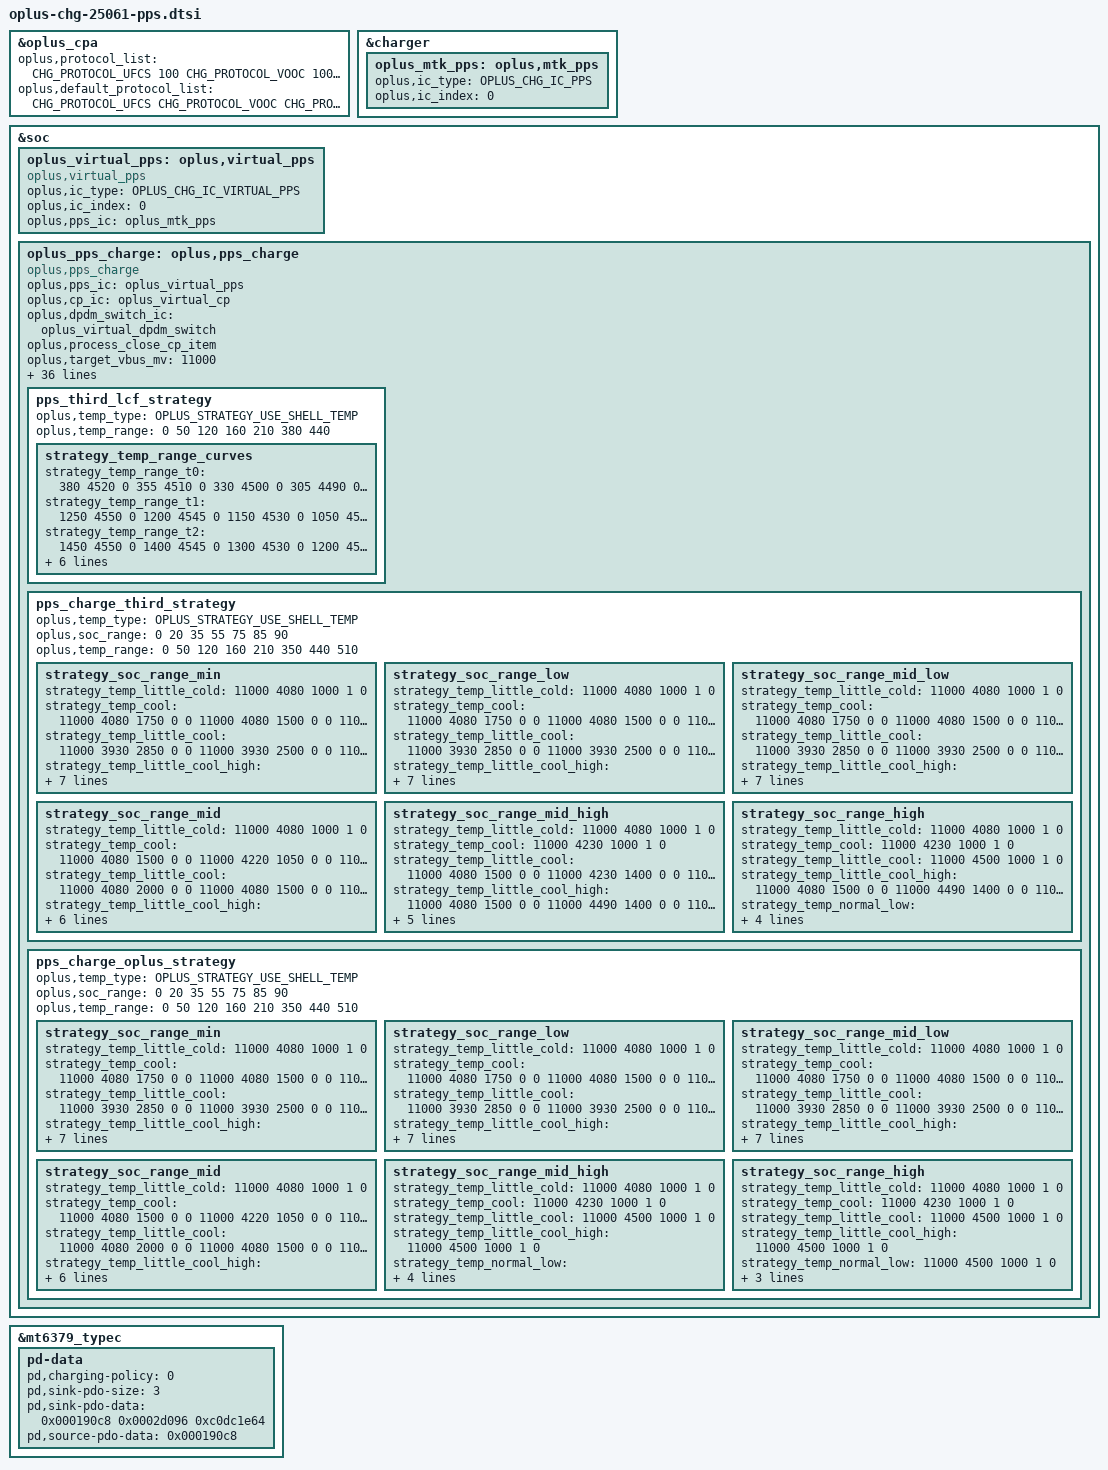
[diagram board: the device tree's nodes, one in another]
//ifdef OPLUS_FEATURE_CHG_BASIC
&oplus_cpa {
	oplus,protocol_list = <CHG_PROTOCOL_UFCS 100
			       CHG_PROTOCOL_VOOC 100
			       CHG_PROTOCOL_PPS 55
			       CHG_PROTOCOL_PD 18
			       CHG_PROTOCOL_QC 18>;
	oplus,default_protocol_list = <CHG_PROTOCOL_UFCS
				       CHG_PROTOCOL_VOOC
				       CHG_PROTOCOL_PPS
				       CHG_PROTOCOL_PD>;
};

&charger {
	oplus_mtk_pps: oplus,mtk_pps {
		oplus,ic_type = <OPLUS_CHG_IC_PPS>;
		oplus,ic_index = <0>;
	};
};
&soc {
	oplus_virtual_pps: oplus,virtual_pps {
		compatible = "oplus,virtual_pps";

		oplus,ic_type = <OPLUS_CHG_IC_VIRTUAL_PPS>;
		oplus,ic_index = <0>;
		oplus,pps_ic = <&oplus_mtk_pps>;
	};
	oplus_pps_charge: oplus,pps_charge {
		compatible = "oplus,pps_charge";
		oplus,pps_ic = <&oplus_virtual_pps>;
		oplus,cp_ic = <&oplus_virtual_cp>;
		oplus,dpdm_switch_ic = <&oplus_virtual_dpdm_switch>;
		oplus,process_close_cp_item;

		oplus,target_vbus_mv = <11000>;
		oplus,curr_max_ma = <5000>;
		oplus,curr_max_ma_percent = <2500 /* 75% ibus */
 					     1000 /* 85% ibus */>;

		oplus,pps_warm_allow_vol = <4000>;
		oplus,pps_warm_allow_soc = <55>;
		oplus,pps_strategy_normal_current = <5000>;
		oplus,pps_over_high_or_low_current = <3000>;
		oplus,pps_timeout_third = <19954>;
		oplus,pps_timeout_oplus = <19954>;
		oplus,pps_ibat_over_third = <11400>;
		oplus,pps_ibat_over_oplus = <11400>;
		oplus,pps_full_cool_sw_vbat = <4230>;
		oplus,pps_full_normal_sw_vbat = <4500>;
		oplus,pps_full_normal_hw_vbat = <4540>;
		oplus,pps_full_warm_vbat = <4130>;
		oplus,pps_full_cool_sw_vbat_third = <4230>;
		oplus,pps_full_normal_sw_vbat_third= <4500>;
		oplus,pps_full_normal_hw_vbat_third = <4540>;
		oplus,pps_current_change_timeout = <100>;
		oplus,pps_strategy_batt_high_temp = <410 430 435 400 425 430>;
		oplus,pps_strategy_high_current = <3000 3000 2000 3000 3000 3000>;
		oplus,pps_little_cool_high_temp = <210>;
		oplus,pps_low_temp = <50>;
		oplus,curve_strategy_name = "pps_ufcs_curve_v2";
		oplus,pps_charge_strategy_soc = <0 20 35 55 75 85 90>;
		oplus,pps_charge_strategy_temp = <50 50 120 160 350 440 510>;
		oplus,pps_full_recheck_temp = <210>;

		oplus,pps_vfa_strategy = <&ratio2t1_vfa_strategy>;

		oplus,plc_strategy-data = <&pps_simple_strategy>;
		oplus,plc_strategy-names = "default";

		oplus,temperature_strategy_name = "cgcl";
		oplus,temperature_strategy_data = < OPLUS_STRATEGY_USE_SHELL_TEMP
							0   400 5000 1 0
							395 420 4000 2 0
							410 430 3000 3 1
							425 440 2500 4 2
							435 450 2000 4 3>;

		pps_third_lcf_strategy {
			oplus,temp_type = <OPLUS_STRATEGY_USE_SHELL_TEMP>;
			oplus,temp_range = <0 50 120 160 210 380 440>;

			strategy_temp_range_curves {
				strategy_temp_range_t0 =	<380 4520 0
								 355 4510 0
								 330 4500 0
								 305 4490 0
								 280 4480 1>;
				strategy_temp_range_t1 =	<1250 4550 0
								 1200 4545 0
								 1150 4530 0
								 1050 4520 0
								 950 4510 1>;
				strategy_temp_range_t2 =	<1450 4550 0
								 1400 4545 0
								 1300 4530 0
								 1200 4520 0
								 1050 4510 1>;
				strategy_temp_range_t3 =	<1550 4550 0
								 1500 4545 0
								 1400 4530 0
								 1300 4520 0
								 1150 4510 1>;
				strategy_temp_range_t4 =	<2100 4543 0
								 1900 4539 0
								 1600 4535 0
								 1300 4525 0
								 1000 4515 1>;
				strategy_temp_range_t5 =	<3550 4543 0
								 3350 4538 0
								 2600 4515 0
								 1850 4500 0
								 1000 4480 1>;
			};
		};

		pps_charge_third_strategy {
			oplus,temp_type = <OPLUS_STRATEGY_USE_SHELL_TEMP>;
			oplus,soc_range = <0 20 35 55 75 85 90>;
			oplus,temp_range = <0 50 120 160 210 350 440 510>;

			strategy_soc_range_min {
				strategy_temp_little_cold =	<11000 4080 1000 1 0>;
				strategy_temp_cool =		<11000 4080 1750 0 0
								11000 4080 1500 0 0
								11000 4220 1050 0 0
								11000 4230 1000 1 0>;
				strategy_temp_little_cool =	<11000 3930 2850 0 0
								11000 3930 2500 0 0
								11000 4080 2100 0 0
								11000 4080 2000 0 0
								11000 4080 1500 0 0
								11000 4230 1400 0 0
								11000 4490 1050 0 0
								11000 4500 1000 1 0>;
				strategy_temp_little_cool_high = <11000 3930 2850 0 0
								11000 3930 2500 0 0
								11000 4080 2100 0 0
								11000 4080 2000 0 0
								11000 4080 1500 0 0
								11000 4490 1400 0 0
								11000 4500 1000 1 0>;
				strategy_temp_normal_low =	<11000 4380 5000 0 0
								11000 4490 4600 0 0
								11000 4490 4500 0 0
								11000 4490 4450 0 0
								11000 4490 4000 0 0
								11000 4490 3500 0 0
								11000 4490 3000 0 0
								11000 4490 2500 0 0
								11000 4490 2000 0 0
								11000 4490 1500 0 0
								11000 4500 1000 1 0>;
				strategy_temp_normal_high =	<11000 4380 5000 0 0
								11000 4475 4600 0 0
								11000 4475 4500 0 0
								11000 4475 4450 0 0
								11000 4475 4000 0 0
								11000 4475 3500 0 0
								11000 4475 3000 0 0
								11000 4475 2500 0 0
								11000 4475 2000 0 0
								11000 4475 1500 0 0
								11000 4485 1000 1 0>;
				strategy_temp_warm =		<11000 4120 2100 0 0
								11000 4120 2000 0 0
								11000 4120 1500 0 0
								11000 4130 1000 1 0>;
			};
			strategy_soc_range_low {
				strategy_temp_little_cold =	<11000 4080 1000 1 0>;
				strategy_temp_cool =		<11000 4080 1750 0 0
								11000 4080 1500 0 0
								11000 4220 1050 0 0
								11000 4230 1000 1 0>;
				strategy_temp_little_cool =	<11000 3930 2850 0 0
								11000 3930 2500 0 0
								11000 4080 2100 0 0
								11000 4080 2000 0 0
								11000 4080 1500 0 0
								11000 4230 1400 0 0
								11000 4490 1050 0 0
								11000 4500 1000 1 0>;
				strategy_temp_little_cool_high = <11000 3930 2850 0 0
								11000 3930 2500 0 0
								11000 4080 2100 0 0
								11000 4080 2000 0 0
								11000 4080 1500 0 0
								11000 4490 1400 0 0
								11000 4500 1000 1 0>;
				strategy_temp_normal_low =	<11000 4380 5000 0 0
								11000 4490 4600 0 0
								11000 4490 4500 0 0
								11000 4490 4450 0 0
								11000 4490 4000 0 0
								11000 4490 3500 0 0
								11000 4490 3000 0 0
								11000 4490 2500 0 0
								11000 4490 2000 0 0
								11000 4490 1500 0 0
								11000 4500 1000 1 0>;
				strategy_temp_normal_high =	<11000 4380 5000 0 0
								11000 4475 4600 0 0
								11000 4475 4500 0 0
								11000 4475 4450 0 0
								11000 4475 4000 0 0
								11000 4475 3500 0 0
								11000 4475 3000 0 0
								11000 4475 2500 0 0
								11000 4475 2000 0 0
								11000 4475 1500 0 0
								11000 4485 1000 1 0>;
				strategy_temp_warm =		<11000 4120 2100 0 0
								11000 4120 2000 0 0
								11000 4120 1500 0 0
								11000 4130 1000 1 0>;
			};
			strategy_soc_range_mid_low {
				strategy_temp_little_cold =	<11000 4080 1000 1 0>;
				strategy_temp_cool =		<11000 4080 1750 0 0
								11000 4080 1500 0 0
								11000 4220 1050 0 0
								11000 4230 1000 1 0>;
				strategy_temp_little_cool =	<11000 3930 2850 0 0
								11000 3930 2500 0 0
								11000 4080 2100 0 0
								11000 4080 2000 0 0
								11000 4080 1500 0 0
								11000 4230 1400 0 0
								11000 4490 1050 0 0
								11000 4500 1000 1 0>;
				strategy_temp_little_cool_high = <11000 3930 2850 0 0
								11000 3930 2500 0 0
								11000 4080 2100 0 0
								11000 4080 2000 0 0
								11000 4080 1500 0 0
								11000 4490 1400 0 0
								11000 4500 1000 1 0>;
				strategy_temp_normal_low =	<11000 4380 5000 0 0
								11000 4490 4600 0 0
								11000 4490 4500 0 0
								11000 4490 4450 0 0
								11000 4490 4000 0 0
								11000 4490 3500 0 0
								11000 4490 3000 0 0
								11000 4490 2500 0 0
								11000 4490 2000 0 0
								11000 4490 1500 0 0
								11000 4500 1000 1 0>;
				strategy_temp_normal_high =	<11000 4380 5000 0 0
								11000 4475 4600 0 0
								11000 4475 4500 0 0
								11000 4475 4450 0 0
								11000 4475 4000 0 0
								11000 4475 3500 0 0
								11000 4475 3000 0 0
								11000 4475 2500 0 0
								11000 4475 2000 0 0
								11000 4475 1500 0 0
								11000 4485 1000 1 0>;
				strategy_temp_warm =		<11000 4120 2100 0 0
								11000 4120 2000 0 0
								11000 4120 1500 0 0
								11000 4130 1000 1 0>;
			};
			strategy_soc_range_mid {
				strategy_temp_little_cold =	<11000 4080 1000 1 0>;
				strategy_temp_cool =		<11000 4080 1500 0 0
								11000 4220 1050 0 0
								11000 4230 1000 1 0>;
				strategy_temp_little_cool =	<11000 4080 2000 0 0
								11000 4080 1500 0 0
								11000 4230 1400 0 0
								11000 4490 1050 0 0
								11000 4500 1000 1 0>;
				strategy_temp_little_cool_high = <11000 3930 2500 0 0
								11000 4080 2100 0 0
								11000 4080 2000 0 0
								11000 4080 1500 0 0
								11000 4490 1400 0 0
								11000 4500 1000 1 0>;
				strategy_temp_normal_low =	<11000 4490 3500 0 0
								11000 4490 3000 0 0
								11000 4490 2500 0 0
								11000 4490 2000 0 0
								11000 4490 1500 0 0
								11000 4500 1000 1 0>;
				strategy_temp_normal_high =	<11000 4475 4000 0 0
								11000 4475 3500 0 0
								11000 4475 3000 0 0
								11000 4475 2500 0 0
								11000 4475 2000 0 0
								11000 4475 1500 0 0
								11000 4485 1000 1 0>;
				strategy_temp_warm =		<11000 4130 1000 1 0>;
			};
			strategy_soc_range_mid_high {
				strategy_temp_little_cold =	<11000 4080 1000 1 0>;
				strategy_temp_cool =		<11000 4230 1000 1 0>;
				strategy_temp_little_cool =	<11000 4080 1500 0 0
								11000 4230 1400 0 0
								11000 4490 1050 0 0
								11000 4500 1000 1 0>;
				strategy_temp_little_cool_high = <11000 4080 1500 0 0
								11000 4490 1400 0 0
								11000 4500 1000 1 0>;
				strategy_temp_normal_low =	<11000 4490 2500 0 0
								11000 4490 2000 0 0
								11000 4490 1500 0 0
								11000 4500 1000 1 0>;
				strategy_temp_normal_high =	<11000 4475 3000 0 0
								11000 4475 2500 0 0
								11000 4475 2000 0 0
								11000 4475 1500 0 0
								11000 4485 1000 1 0>;
				strategy_temp_warm =		<11000 4130 1000 1 0>;
			};
			strategy_soc_range_high {
				strategy_temp_little_cold =	<11000 4080 1000 1 0>;
				strategy_temp_cool =		<11000 4230 1000 1 0>;
				strategy_temp_little_cool =	<11000 4500 1000 1 0>;
				strategy_temp_little_cool_high = <11000 4080 1500 0 0
								11000 4490 1400 0 0
								11000 4500 1000 1 0>;
				strategy_temp_normal_low =	<11000 4490 1500 0 0
								11000 4500 1000 1 0>;
				strategy_temp_normal_high =	<11000 4475 2000 0 0
								11000 4475 1500 0 0
								11000 4485 1000 1 0>;
				strategy_temp_warm =		<11000 4130 1000 1 0>;
			};
		};

		pps_charge_oplus_strategy {
			oplus,temp_type = <OPLUS_STRATEGY_USE_SHELL_TEMP>;
			oplus,soc_range = <0 20 35 55 75 85 90>;
			oplus,temp_range = <0 50 120 160 210 350 440 510>;

			strategy_soc_range_min {
				strategy_temp_little_cold =	<11000 4080 1000 1 0>;
				strategy_temp_cool =		<11000 4080 1750 0 0
								11000 4080 1500 0 0
								11000 4220 1050 0 0
								11000 4230 1000 1 0>;
				strategy_temp_little_cool =	<11000 3930 2850 0 0
								11000 3930 2500 0 0
								11000 4080 2100 0 0
								11000 4080 2000 0 0
								11000 4080 1500 0 0
								11000 4230 1400 0 0
								11000 4490 1050 0 0
								11000 4500 1000 1 0>;
				strategy_temp_little_cool_high = <11000 3930 2850 0 0
								11000 3930 2500 0 0
								11000 4080 2100 0 0
								11000 4080 2000 0 0
								11000 4080 1500 0 0
								11000 4490 1400 0 0
								11000 4500 1000 1 0>;
				strategy_temp_normal_low =	<11000 4380 5000 0 0
								11000 4490 4600 0 0
								11000 4490 4500 0 0
								11000 4490 4450 0 0
								11000 4490 4000 0 0
								11000 4490 3500 0 0
								11000 4490 3000 0 0
								11000 4490 2500 0 0
								11000 4490 2000 0 0
								11000 4490 1500 0 0
								11000 4500 1000 1 0>;
				strategy_temp_normal_high =	<11000 4380 5000 0 0
								11000 4475 4600 0 0
								11000 4475 4500 0 0
								11000 4475 4450 0 0
								11000 4475 4000 0 0
								11000 4475 3500 0 0
								11000 4475 3000 0 0
								11000 4475 2500 0 0
								11000 4475 2000 0 0
								11000 4475 1500 0 0
								11000 4485 1000 1 0>;
				strategy_temp_warm =		<11000 4120 2000 0 0
								11000 4120 1500 0 0
								11000 4130 1000 1 0>;
			};
			strategy_soc_range_low {
				strategy_temp_little_cold =	<11000 4080 1000 1 0>;
				strategy_temp_cool =		<11000 4080 1750 0 0
								11000 4080 1500 0 0
								11000 4220 1050 0 0
								11000 4230 1000 1 0>;
				strategy_temp_little_cool =	<11000 3930 2850 0 0
								11000 3930 2500 0 0
								11000 4080 2100 0 0
								11000 4080 2000 0 0
								11000 4080 1500 0 0
								11000 4230 1400 0 0
								11000 4490 1050 0 0
								11000 4500 1000 1 0>;
				strategy_temp_little_cool_high = <11000 3930 2850 0 0
								11000 3930 2500 0 0
								11000 4080 2100 0 0
								11000 4080 2000 0 0
								11000 4080 1500 0 0
								11000 4490 1400 0 0
								11000 4500 1000 1 0>;
				strategy_temp_normal_low =	<11000 4380 5000 0 0
								11000 4490 4600 0 0
								11000 4490 4500 0 0
								11000 4490 4450 0 0
								11000 4490 4000 0 0
								11000 4490 3500 0 0
								11000 4490 3000 0 0
								11000 4490 2500 0 0
								11000 4490 2000 0 0
								11000 4490 1500 0 0
								11000 4500 1000 1 0>;
				strategy_temp_normal_high =	<11000 4380 5000 0 0
								11000 4475 4600 0 0
								11000 4475 4500 0 0
								11000 4475 4450 0 0
								11000 4475 4000 0 0
								11000 4475 3500 0 0
								11000 4475 3000 0 0
								11000 4475 2500 0 0
								11000 4475 2000 0 0
								11000 4475 1500 0 0
								11000 4485 1000 1 0>;
				strategy_temp_warm =		<11000 4120 2000 0 0
								11000 4120 1500 0 0
								11000 4130 1000 1 0>;
			};
			strategy_soc_range_mid_low {
				strategy_temp_little_cold =	<11000 4080 1000 1 0>;
				strategy_temp_cool =		<11000 4080 1750 0 0
								11000 4080 1500 0 0
								11000 4220 1050 0 0
								11000 4230 1000 1 0>;
				strategy_temp_little_cool =	<11000 3930 2850 0 0
								11000 3930 2500 0 0
								11000 4080 2100 0 0
								11000 4080 2000 0 0
								11000 4080 1500 0 0
								11000 4230 1400 0 0
								11000 4490 1050 0 0
								11000 4500 1000 1 0>;
				strategy_temp_little_cool_high = <11000 3930 2850 0 0
								11000 3930 2500 0 0
								11000 4080 2100 0 0
								11000 4080 2000 0 0
								11000 4080 1500 0 0
								11000 4490 1400 0 0
								11000 4500 1000 1 0>;
				strategy_temp_normal_low =	<11000 4380 5000 0 0
								11000 4490 4600 0 0
								11000 4490 4500 0 0
								11000 4490 4450 0 0
								11000 4490 4000 0 0
								11000 4490 3500 0 0
								11000 4490 3000 0 0
								11000 4490 2500 0 0
								11000 4490 2000 0 0
								11000 4490 1500 0 0
								11000 4500 1000 1 0>;
				strategy_temp_normal_high =	<11000 4380 5000 0 0
								11000 4475 4600 0 0
								11000 4475 4500 0 0
								11000 4475 4450 0 0
								11000 4475 4000 0 0
								11000 4475 3500 0 0
								11000 4475 3000 0 0
								11000 4475 2500 0 0
								11000 4475 2000 0 0
								11000 4475 1500 0 0
								11000 4485 1000 1 0>;
				strategy_temp_warm =		<11000 4120 2000 0 0
								11000 4120 1500 0 0
								11000 4130 1000 1 0>;
			};
			strategy_soc_range_mid {
				strategy_temp_little_cold =	<11000 4080 1000 1 0>;
				strategy_temp_cool =		<11000 4080 1500 0 0
								11000 4220 1050 0 0
								11000 4230 1000 1 0>;
				strategy_temp_little_cool =	<11000 4080 2000 0 0
								11000 4080 1500 0 0
								11000 4230 1400 0 0
								11000 4490 1050 0 0
								11000 4500 1000 1 0>;
				strategy_temp_little_cool_high = <11000 4080 2000 0 0
								11000 4080 1500 0 0
								11000 4490 1400 0 0
								11000 4500 1000 1 0>;
				strategy_temp_normal_low =	<11000 4490 2000 0 0
								11000 4490 1500 0 0
								11000 4500 1000 1 0>;
				strategy_temp_normal_high =	<11000 4475 2500 0 0
								11000 4475 2000 0 0
								11000 4475 1500 0 0
								11000 4485 1000 1 0>;
				strategy_temp_warm =		<11000 4130 1000 1 0>;
			};
			strategy_soc_range_mid_high {
				strategy_temp_little_cold =	<11000 4080 1000 1 0>;
				strategy_temp_cool =		<11000 4230 1000 1 0>;
				strategy_temp_little_cool =	<11000 4500 1000 1 0>;
				strategy_temp_little_cool_high = <11000 4500 1000 1 0>;
				strategy_temp_normal_low =	<11000 4490 1500 0 0
								11000 4500 1000 1 0>;
				strategy_temp_normal_high =	<11000 4475 1500 0 0
								11000 4485 1000 1 0>;
				strategy_temp_warm =		<11000 4130 1000 1 0>;
			};
			strategy_soc_range_high {
				strategy_temp_little_cold =	<11000 4080 1000 1 0>;
				strategy_temp_cool =		<11000 4230 1000 1 0>;
				strategy_temp_little_cool =	<11000 4500 1000 1 0>;
				strategy_temp_little_cool_high = <11000 4500 1000 1 0>;
				strategy_temp_normal_low =	<11000 4500 1000 1 0>;
				strategy_temp_normal_high =	<11000 4475 1500 0 0
								11000 4485 1000 1 0>;
				strategy_temp_warm =		<11000 4130 1000 1 0>;
			};
		};
	};
};

&mt6379_typec {
	pd-data {
		pd,charging-policy = <0>;
		pd,sink-pdo-size = <3>;
		pd,sink-pdo-data = <0x000190c8 0x0002d096 0xc0dc1e64>;
		pd,source-pdo-data = <0x000190c8>;/* Fixed, 5000mV, 2000mA*/
	};
};
//#endif OPLUS_FEATURE_CHG_BASIC
